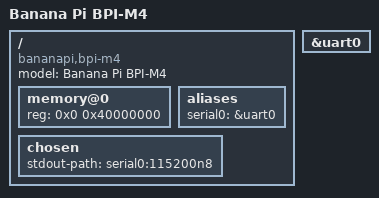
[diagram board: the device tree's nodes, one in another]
// SPDX-License-Identifier: (GPL-2.0-or-later OR BSD-2-Clause)
/*
 * Copyright (c) 2019 Andreas Färber
 */

/dts-v1/;

#include "rtd1395.dtsi"

/ {
	compatible = "bananapi,bpi-m4", "realtek,rtd1395";
	model = "Banana Pi BPI-M4";

	memory@0 {
		device_type = "memory";
		reg = <0x0 0x40000000>; /* 1 GiB or 2 GiB */
	};

	aliases {
		serial0 = &uart0;
	};

	chosen {
		stdout-path = "serial0:115200n8";
	};
};

&uart0 {
	status = "okay";
};
